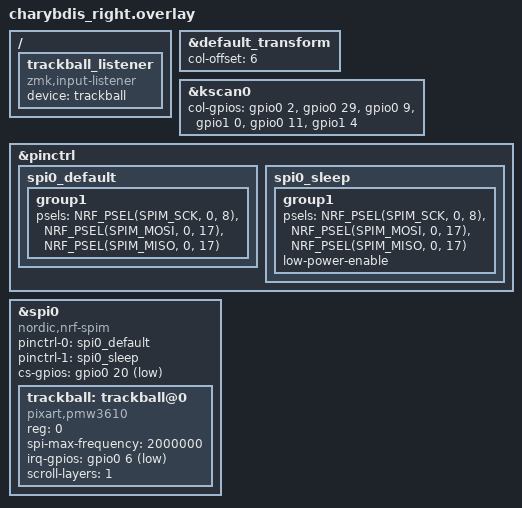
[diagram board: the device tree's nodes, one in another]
#include "charybdis.dtsi"

&default_transform {
    col-offset = <6>;
};

&kscan0 {
    col-gpios
        = <&gpio0 2  (GPIO_ACTIVE_HIGH | GPIO_PULL_DOWN)>
        , <&gpio0 29 (GPIO_ACTIVE_HIGH | GPIO_PULL_DOWN)>
        , <&gpio0 9  (GPIO_ACTIVE_HIGH | GPIO_PULL_DOWN)>
        , <&gpio1 0  (GPIO_ACTIVE_HIGH | GPIO_PULL_DOWN)>
        , <&gpio0 11 (GPIO_ACTIVE_HIGH | GPIO_PULL_DOWN)>
        , <&gpio1 4  (GPIO_ACTIVE_HIGH | GPIO_PULL_DOWN)>
        ;
};

/* === PMW3610 트랙볼 === */
&pinctrl {
    spi0_default: spi0_default {
        group1 {
            psels = <NRF_PSEL(SPIM_SCK,  0, 8)>,
                    <NRF_PSEL(SPIM_MOSI, 0, 17)>,
                    <NRF_PSEL(SPIM_MISO, 0, 17)>;
        };
    };

    spi0_sleep: spi0_sleep {
        group1 {
            psels = <NRF_PSEL(SPIM_SCK,  0, 8)>,
                    <NRF_PSEL(SPIM_MOSI, 0, 17)>,
                    <NRF_PSEL(SPIM_MISO, 0, 17)>;
            low-power-enable;
        };
    };
};

&spi0 {
    status = "okay";
    compatible = "nordic,nrf-spim";
    pinctrl-0 = <&spi0_default>;
    pinctrl-1 = <&spi0_sleep>;
    pinctrl-names = "default", "sleep";
    cs-gpios = <&gpio0 20 GPIO_ACTIVE_LOW>;

    trackball: trackball@0 {
        status = "okay";
        compatible = "pixart,pmw3610";
        reg = <0>;
        spi-max-frequency = <2000000>;
        irq-gpios = <&gpio0 6 (GPIO_ACTIVE_LOW | GPIO_PULL_UP)>;

        /* 여기서부터 드라이버 옵션 */

        // 0번 레이어에서는 안 쓸 거라 했고,
        // 2번 레이어를 "마우스 레이어"로 쓸 거면
        // automouse-layer = <2>;  // 나중에 자동 마우스 레이어 쓰고 싶으면 이거 켜면 됨

        // 스크롤 전용 레이어 따로 만들면:
        scroll-layers = <1>;    // 예: 1번 레이어를 스크롤 레이어로
    };
};

/* 트랙볼 이벤트 리스너 */
 / {
    trackball_listener {
        compatible = "zmk,input-listener";
        device = <&trackball>;
    };
};
